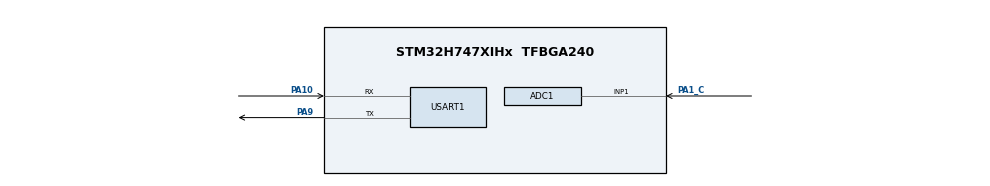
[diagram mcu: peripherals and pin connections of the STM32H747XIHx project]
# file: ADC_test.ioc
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ADC1.Channel-3\#ChannelRegularConversion=ADC_CHANNEL_1
ADC1.NbrOfConversionFlag=1
ADC1.OffsetNumber-3\#ChannelRegularConversion=ADC_OFFSET_NONE
ADC1.OffsetSignedSaturation-3\#ChannelRegularConversion=DISABLE
ADC1.Rank-3\#ChannelRegularConversion=1
ADC1.SamplingTime-3\#ChannelRegularConversion=ADC_SAMPLETIME_810CYCLES_5
ADC1.master=1
CortexM4.IPs=BDMA,DMA,FATFS_M4\:I,FREERTOS_M4\:I,IWDG2\:I,MDMA,NVIC2\:I,RCC,USB_DEVICE_M4\:I,USB_HOST_M4\:I,WWDG2\:I,DCMI\:I,TIM3\:I,DEBUG,PDM2PCM_M4\:I,PWR,RESMGR_UTILITY,SYS_M4\:I,CORTEX_M4\:I,OPENAMP_M4\:I,VREFBUF,GPIO
CortexM7.IPs=BDMA\:I,DMA\:I,FATFS_M7\:I,FREERTOS_M7\:I,IWDG1\:I,MDMA\:I,NVIC1\:I,RCC\:I,USB_DEVICE_M7\:I,USB_HOST_M7\:I,WWDG1\:I,CORTEX_M7\:I,DEBUG\:I,PDM2PCM_M7\:I,PWR\:I,RESMGR_UTILITY\:I,SYS\:I,OPENAMP_M7\:I,VREFBUF\:I,GPIO\:I,ADC1\:I,USART1\:I
Mcu.Family=STM32H7
Mcu.Name=STM32H747XIHx
Mcu.Package=TFBGA240
NVIC1.PriorityGroup=NVIC_PRIORITYGROUP_4
NVIC2.PriorityGroup=NVIC_PRIORITYGROUP_4
PA10.GPIO_Speed=GPIO_SPEED_FREQ_HIGH
PA10.Mode=Asynchronous
PA10.PinAttribute=CortexM7
PA10.Signal=USART1_RX
PA1_C.PinAttribute=CortexM7
PA1_C.Signal=ADCx_INP1
PA9.GPIO_Speed=GPIO_SPEED_FREQ_HIGH
PA9.Mode=Asynchronous
PA9.PinAttribute=CortexM7
PA9.Signal=USART1_TX
PH0-OSC_IN\ (PH0).Mode=HSE-External-Oscillator
PH0-OSC_IN\ (PH0).PinAttribute=Free
PH0-OSC_IN\ (PH0).Signal=RCC_OSC_IN
PH1-OSC_OUT\ (PH1).Mode=HSE-External-Oscillator
PH1-OSC_OUT\ (PH1).PinAttribute=Free
PH1-OSC_OUT\ (PH1).Signal=RCC_OSC_OUT
ProjectManager.HeapSize=M4-0x200,M7-0x200
ProjectManager.StackSize=M4-0x400,M7-0x400
ProjectManager.TargetToolchain=STM32CubeIDE
RCC.ADCFreq_Value=95468750
RCC.APB1Freq_Value=100000000
RCC.APB2Freq_Value=100000000
RCC.APB3Freq_Value=100000000
RCC.APB4Freq_Value=100000000
RCC.CortexFreq_Value=400000000
RCC.D1PPRE=RCC_APB3_DIV2
RCC.D2PPRE1=RCC_APB1_DIV2
RCC.D2PPRE2=RCC_APB2_DIV2
RCC.D3PPRE=RCC_APB4_DIV2
RCC.DIVM1=5
RCC.DIVM2=4
RCC.DIVN1=160
RCC.DIVN2=76
RCC.DIVP2=5
RCC.HCLKFreq_Value=200000000
RCC.HPRE=RCC_HCLK_DIV2
RCC.PLL2FRACN=3072
RCC.PLLSourceVirtual=RCC_PLLSOURCE_HSE
RCC.PWR_Regulator_Voltage_Scale=PWR_REGULATOR_VOLTAGE_SCALE1
RCC.SYSCLKFreq_VALUE=400000000
RCC.SYSCLKSource=RCC_SYSCLKSOURCE_PLLCLK
RCC.SupplySource=PWR_DIRECT_SMPS_SUPPLY
RCC.USBFreq_Value=400000000
SH.ADCx_INP1.0=ADC1_INP1,IN1-Single-Ended
USART1.VirtualMode-Asynchronous=VM_ASYNC
VP_SYS_M4_VS_Systick.Mode=SysTick
board=STM32H747I-DISCO

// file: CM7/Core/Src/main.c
/* USER CODE BEGIN Header */
/**
  ******************************************************************************
  * @file           : main.c
  * @brief          : Main program body
  ******************************************************************************
  * @attention
  *
  * Copyright (c) 2024 STMicroelectronics.
  * All rights reserved.
  *
  * This software is licensed under terms that can be found in the LICENSE file
  * in the root directory of this software component.
  * If no LICENSE file comes with this software, it is provided AS-IS.
  *
  ******************************************************************************
  */
/* USER CODE END Header */
#include "main.h"

/* USER CODE BEGIN Includes */
#include "string.h"
#include "stdio.h"
/* USER CODE END Includes */

/* USER CODE BEGIN PD */

#ifndef HSEM_ID_0
#define HSEM_ID_0 (0U) /* HW semaphore 0*/
#endif

/* USER CODE END PD */

/* USER CODE BEGIN PM */
#define V_REF 3.3

/* USER CODE END PM */

ADC_HandleTypeDef hadc1;

UART_HandleTypeDef huart1;

/* USER CODE BEGIN PV */
float voltage;
/* USER CODE END PV */

void SystemClock_Config(void);
static void MX_GPIO_Init(void);
static void MX_ADC1_Init(void);
static void MX_USART1_UART_Init(void);

/* USER CODE BEGIN 0 */
uint16_t ADC_VALUE = 0;
uint16_t count = 0;
char uart_buffer[20];
/* USER CODE END 0 */

int main(void)
{

/* USER CODE BEGIN Boot_Mode_Sequence_0 */
//  int32_t timeout;
/* USER CODE END Boot_Mode_Sequence_0 */

/* USER CODE BEGIN Boot_Mode_Sequence_1 */
  /* Wait until CPU2 boots and enters in stop mode or timeout*/
//  timeout = 0xFFFF;
//  while((__HAL_RCC_GET_FLAG(RCC_FLAG_D2CKRDY) != RESET) && (timeout-- > 0));
//  if ( timeout < 0 )
//  {
//  Error_Handler();
//  }
/* USER CODE END Boot_Mode_Sequence_1 */
  /* MCU Configuration--------------------------------------------------------*/

  /* Reset of all peripherals, Initializes the Flash interface and the Systick. */
  HAL_Init();

  /* Configure the system clock */
  SystemClock_Config();
/* USER CODE BEGIN Boot_Mode_Sequence_2 */

/* USER CODE END Boot_Mode_Sequence_2 */

  /* Initialize all configured peripherals */
  MX_GPIO_Init();
  MX_ADC1_Init();
  MX_USART1_UART_Init();

  /* Infinite loop */
  while (1)
  {

    /* USER CODE BEGIN 3 */

	  HAL_ADC_Start(&hadc1);
	     if (HAL_ADC_PollForConversion(&hadc1, 100) == HAL_OK) {
	         ADC_VALUE = HAL_ADC_GetValue(&hadc1);
	     }
	     	 voltage = (ADC_VALUE*V_REF)/65535;
	     sprintf(uart_buffer, "ADC Value: %u\r\n", ADC_VALUE);
	     HAL_UART_Transmit(&huart1, (uint8_t *)uart_buffer, strlen(uart_buffer), HAL_MAX_DELAY);
	     sprintf(uart_buffer, "ADC volt: %.2f\r\n",voltage);
		 HAL_UART_Transmit(&huart1, (uint8_t *)uart_buffer, strlen(uart_buffer), HAL_MAX_DELAY);

	     HAL_ADC_Stop(&hadc1);
	     HAL_Delay(2000);

  }
  /* USER CODE END 3 */
}

void SystemClock_Config(void)
{
  RCC_OscInitTypeDef RCC_OscInitStruct = {0};
  RCC_ClkInitTypeDef RCC_ClkInitStruct = {0};

  /** Supply configuration update enable
  */
  HAL_PWREx_ConfigSupply(PWR_DIRECT_SMPS_SUPPLY);

  /** Configure the main internal regulator output voltage
  */
  __HAL_PWR_VOLTAGESCALING_CONFIG(PWR_REGULATOR_VOLTAGE_SCALE1);

  while(!__HAL_PWR_GET_FLAG(PWR_FLAG_VOSRDY)) {}

  /** Initializes the RCC Oscillators according to the specified parameters
  * in the RCC_OscInitTypeDef structure.
  */
  RCC_OscInitStruct.OscillatorType = RCC_OSCILLATORTYPE_HSE;
  RCC_OscInitStruct.HSEState = RCC_HSE_ON;
  RCC_OscInitStruct.PLL.PLLState = RCC_PLL_ON;
  RCC_OscInitStruct.PLL.PLLSource = RCC_PLLSOURCE_HSE;
  RCC_OscInitStruct.PLL.PLLM = 5;
  RCC_OscInitStruct.PLL.PLLN = 160;
  RCC_OscInitStruct.PLL.PLLP = 2;
  RCC_OscInitStruct.PLL.PLLQ = 2;
  RCC_OscInitStruct.PLL.PLLR = 2;
  RCC_OscInitStruct.PLL.PLLRGE = RCC_PLL1VCIRANGE_2;
  RCC_OscInitStruct.PLL.PLLVCOSEL = RCC_PLL1VCOWIDE;
  RCC_OscInitStruct.PLL.PLLFRACN = 0;
  if (HAL_RCC_OscConfig(&RCC_OscInitStruct) != HAL_OK)
  {
    Error_Handler();
  }

  /** Initializes the CPU, AHB and APB buses clocks
  */
  RCC_ClkInitStruct.ClockType = RCC_CLOCKTYPE_HCLK|RCC_CLOCKTYPE_SYSCLK
                              |RCC_CLOCKTYPE_PCLK1|RCC_CLOCKTYPE_PCLK2
                              |RCC_CLOCKTYPE_D3PCLK1|RCC_CLOCKTYPE_D1PCLK1;
  RCC_ClkInitStruct.SYSCLKSource = RCC_SYSCLKSOURCE_PLLCLK;
  RCC_ClkInitStruct.SYSCLKDivider = RCC_SYSCLK_DIV1;
  RCC_ClkInitStruct.AHBCLKDivider = RCC_HCLK_DIV2;
  RCC_ClkInitStruct.APB3CLKDivider = RCC_APB3_DIV2;
  RCC_ClkInitStruct.APB1CLKDivider = RCC_APB1_DIV2;
  RCC_ClkInitStruct.APB2CLKDivider = RCC_APB2_DIV2;
  RCC_ClkInitStruct.APB4CLKDivider = RCC_APB4_DIV2;

  if (HAL_RCC_ClockConfig(&RCC_ClkInitStruct, FLASH_LATENCY_2) != HAL_OK)
  {
    Error_Handler();
  }
}

static void MX_ADC1_Init(void)
{

  ADC_MultiModeTypeDef multimode = {0};
  ADC_ChannelConfTypeDef sConfig = {0};

  /** Common config
  */
  hadc1.Instance = ADC1;
  hadc1.Init.ScanConvMode = ADC_SCAN_DISABLE;
  hadc1.Init.EOCSelection = ADC_EOC_SINGLE_CONV;
  hadc1.Init.LowPowerAutoWait = DISABLE;
  hadc1.Init.ContinuousConvMode = DISABLE;
  hadc1.Init.NbrOfConversion = 1;
  hadc1.Init.DiscontinuousConvMode = DISABLE;
  hadc1.Init.ExternalTrigConv = ADC_SOFTWARE_START;
  hadc1.Init.ExternalTrigConvEdge = ADC_EXTERNALTRIGCONVEDGE_NONE;
  hadc1.Init.ConversionDataManagement = ADC_CONVERSIONDATA_DR;
  hadc1.Init.Overrun = ADC_OVR_DATA_PRESERVED;
  hadc1.Init.LeftBitShift = ADC_LEFTBITSHIFT_NONE;
  hadc1.Init.OversamplingMode = DISABLE;
  hadc1.Init.Oversampling.Ratio = 1;
  if (HAL_ADC_Init(&hadc1) != HAL_OK)
  {
    Error_Handler();
  }
  hadc1.Init.ClockPrescaler = ADC_CLOCK_ASYNC_DIV1;
  hadc1.Init.Resolution = ADC_RESOLUTION_16B;
  if (HAL_ADC_Init(&hadc1) != HAL_OK)
  {
    Error_Handler();
  }

  /** Configure the ADC multi-mode
  */
  multimode.Mode = ADC_MODE_INDEPENDENT;
  if (HAL_ADCEx_MultiModeConfigChannel(&hadc1, &multimode) != HAL_OK)
  {
    Error_Handler();
  }

  /** Configure Regular Channel
  */
  sConfig.Channel = ADC_CHANNEL_1;
  sConfig.Rank = ADC_REGULAR_RANK_1;
  sConfig.SamplingTime = ADC_SAMPLETIME_810CYCLES_5;
  sConfig.SingleDiff = ADC_SINGLE_ENDED;
  sConfig.OffsetNumber = ADC_OFFSET_NONE;
  sConfig.Offset = 0;
  sConfig.OffsetSignedSaturation = DISABLE;
  if (HAL_ADC_ConfigChannel(&hadc1, &sConfig) != HAL_OK)
  {
    Error_Handler();
  }

}

static void MX_USART1_UART_Init(void)
{

  huart1.Instance = USART1;
  huart1.Init.BaudRate = 115200;
  huart1.Init.WordLength = UART_WORDLENGTH_8B;
  huart1.Init.StopBits = UART_STOPBITS_1;
  huart1.Init.Parity = UART_PARITY_NONE;
  huart1.Init.Mode = UART_MODE_TX_RX;
  huart1.Init.HwFlowCtl = UART_HWCONTROL_NONE;
  huart1.Init.OverSampling = UART_OVERSAMPLING_16;
  huart1.Init.OneBitSampling = UART_ONE_BIT_SAMPLE_DISABLE;
  huart1.Init.ClockPrescaler = UART_PRESCALER_DIV1;
  huart1.AdvancedInit.AdvFeatureInit = UART_ADVFEATURE_NO_INIT;
  if (HAL_UART_Init(&huart1) != HAL_OK)
  {
    Error_Handler();
  }
  if (HAL_UARTEx_SetTxFifoThreshold(&huart1, UART_TXFIFO_THRESHOLD_1_8) != HAL_OK)
  {
    Error_Handler();
  }
  if (HAL_UARTEx_SetRxFifoThreshold(&huart1, UART_RXFIFO_THRESHOLD_1_8) != HAL_OK)
  {
    Error_Handler();
  }
  if (HAL_UARTEx_DisableFifoMode(&huart1) != HAL_OK)
  {
    Error_Handler();
  }

}

static void MX_GPIO_Init(void)
{

  /* GPIO Ports Clock Enable */
  __HAL_RCC_GPIOA_CLK_ENABLE();

}

void Error_Handler(void)
{
  __disable_irq();
  while (1)
  {
  }
}
